# STM32WB09 register map
File version: 1.0
CPU: CM0+ r0p0, little endian, MPU, no FPU, 2 interrupt priority bits
Registers are 32-bit, read-write, reset 0x0 unless marked. A register's access mark holds for its fields unless they carry their own. Offsets are from the block's base; [hi:lo] are bit positions; {n}, {i} and the like mark numbered series.

## PWRC
Base 0x48500000
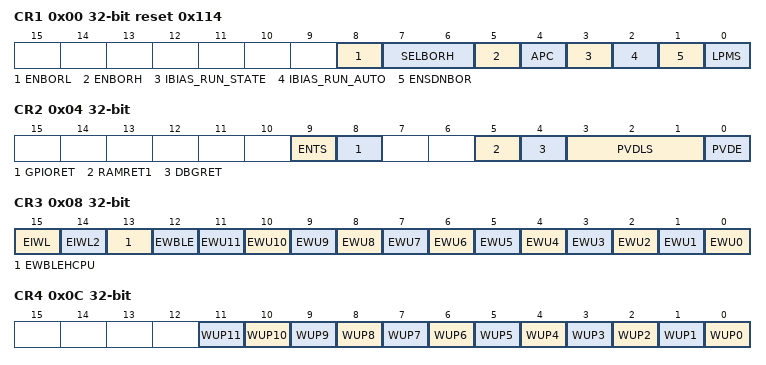
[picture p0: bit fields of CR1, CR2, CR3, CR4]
0x00 CR1 reset 0x114
  [8] ENBORL — ENBORL: Enable BORL reset supervising during RUN mode. 0: No BORL is monitored during RUN mode. 1: BORL is monitored during RUN mode (a POR reset will happen if VDDIO goes below 1.6V during RUN mode) (default). Note: Enabling this feature prevents blocking the device if VDDIO goes below supported voltages during RUN.
  [7:6] SELBORH — SELBORH[1:0]: BORH selection of Vbor threshold
  [5] ENBORH — ENBORH: enable BORH configuration
  [4] APC — APC Apply Pull-up and pull-down configuration from CPU
  [3] IBIAS_RUN_STATE — IBIAS_RUN_STATE: Enable/Disable IBIAS during RUN mode when automatic mode is disabled. 0: IBIAS control is disabled (default). 1: IBIAS control is enabled.
  [2] IBIAS_RUN_AUTO — IBIAS_RUN_AUTO: Enable automatic IBIAS control during RUN/DEEPSTOP mode. 0: IBIAS control is manual (and controlled by IBIAS_RUN_STATE register) 1: IBIAS control is automatic (default).
  [1] ENSDNBOR — ENSDNBOR: Enable BOR supply monitoring during shutdown mode.
  [0] LPMS — LPMS Low Power Mode Selection Selection of the low power mode entered when CPU enters DEEP SLEEP mode and BLE is rdy2sleep.
0x04 CR2
  [9] ENTS — ENTS: Enable Temperature Sensor
  [8] GPIORET — GPIORET: GPIO retention enable. 0: GPIO don't retain their status during DEEPSTOP and exiting from DEEPSTOP (default) 1: GPIO retain their status during DEEPSTOP and exiting from DEEPSTOP. Note: it's mandatory to ensure this bit is set before entering DEEPSTOP unless DBRG.DEEPSTOP2 bit is set.
  [5] RAMRET1 — RAMRET1: RAM1 retention during low power mode
  [4] DBGRET — DBGRET: PA2 and PA3 retention enable after DEEPSTOP 0: PA2, PA3 don't retain their status exiting from DEEPSTOP. (default) 1: PA2, PA3 retain their status exiting from DEEPSTOP.
  [3:1] PVDLS — PVDLS[2:0] Programmable Voltage Detector Level selection then PVDO=1)
  [0] PVDE — PVDE Programmable Voltage Detector Enable When this bit is set the Power Voltage Detector is enabled
0x08 CR3
  [15] EIWL — EIWL: Enable wakeup on Internal event (RTC). 0: Wakeup on internal line is disabled (default). 1: Wakeup on internal line is enabled.
  [14] EIWL2 — EIWL2: Enable wakeup on Internal event (LPUART). 0: Wakeup on internal line is disabled (default). 1: Wakeup on internal line is enabled.
  [13] EWBLEHCPU — EWBLEHCPU: Enable wakeup on BLE Host CPU event. 0: Wakeup on BLE Host CPU line is disabled (default). 1: Wakeup on BLE Host CPU line is enabled.
  [12] EWBLE — EWBLE: Enable wakeup on BLE event. 0: Wakeup on BLE line is disabled (default). 1: Wakeup on BLE line is enabled.
  [n] EWU{n} (n=8..11) — EWU{n} Enable WakeUp line {n} (PA{n}) When this bit is set the wakeup line {n} is enabled and a rising or falling edge on wakeup line {n} will trigger a CPU wakeup event depending on CR4.WP{n} bit.
  [n] EWU{n} (n=0..7) — EWU{n} Enable WakeUp line {n} (PB{n}) When this bit is set the wakeup line {n} is enabled and a rising or falling edge on wakeup line {n} will trigger a CPU wakeup event depending on CR4.WP{n} bit.
0x0C CR4
  [n] WUP{n} (n=8..11) — WUP{n} Wake-up Line Polarity {n} (PA{n}) This bit defines the polarity used for event detection on external wake-up line {n}
  [n] WUP{n} (n=0..7) — WUP{n} Wake-up Line Polarity {n} (PB{n}) This bit defines the polarity used for event detection on external wake-up line {n}
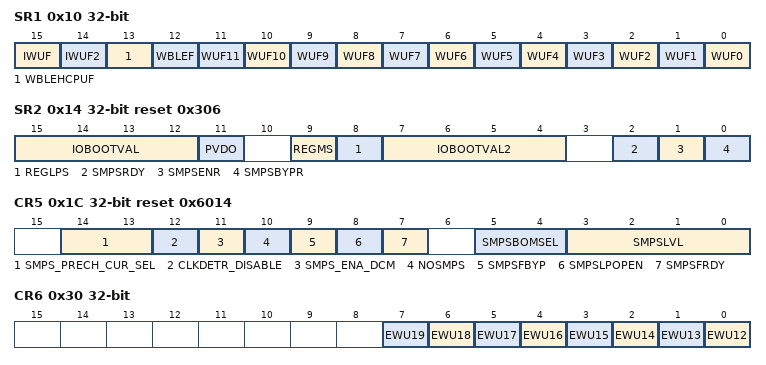
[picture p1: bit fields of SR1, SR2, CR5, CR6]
0x10 SR1
  [15] IWUF ro — IWUF: Internal wakeup flag (RTC). 0: no wakeup from RTC occurred since last clear. 1: a wakeup from RTC occurred since last clear. Note: The user must clear the RTC wakeup flag inside the RTC IP to clear this bit (mirror of the RTC wakeup line on the PWRC block).
  [14] IWUF2 ro — IWUF2: Internal wakeup 2 flag (LPUART). 0: no wakeup from LPUART occurred since last clear. 1: a wakeup from LPUART occurred since last clear. Note: The user must clear the LPUART wakeup flag inside the LPUART IP to clear this bit (mirror of the LPUART wakeup line on the PWRC block).
  [13] WBLEHCPUF — WBLEHCPUF: BLE Host CPU wakeup flag. 0: no wakeup from BLE Host CPU occurred since last clear. 1: a wakeup from BLE Host CPU occurred since last clear. Cleared by writing 1 in this bit.
  [12] WBLEF — WBLEF: BLE wakeup flag. 0: no wakeup from BLE occurred since last clear. 1: a wakeup from BLE occurred since last clear. Cleared by writing 1 in this bit.
  [n] WUF{n} (n=8..11) — WUF{n} WakeUp Flag {n} (PA{n}) This bit is set when a wakeup is detected on wakeup line {n}. It is cleared by a reset pad or by writing 1 in this bit field. writting this bit, clears the interrupt:
  [n] WUF{n} (n=0..7) — WUF{n} WakeUp Flag {n} (PB{n}) This bit is set when a wakeup is detected on wakeup line {n}. It is cleared by a reset pad or by writing 1 in this bit field. writting this bit, clears the interrupt:
0x14 SR2 ro reset 0x306
  [15:12] IOBOOTVAL — Bit3: PA11 input value on VDD33 latched at POR Bit2: PA10 input value on VDD33 latched at POR Bit1: PA9 input value on VDD33 latched at POR Bit0: PA8 input value on VDD33 latched at POR
  [11] PVDO — PVDO: Power Voltage Detector Output When the Power Voltage Detector is enabled (CR2.PVDE) this bit is set when the system supply (VDDIO) is lower than the selected PVD threshold (CR2.PVDLS)
  [9] REGMS — REGMS: Regulator Main LDO Started This bit provides the information whether main regulator is ready.
  [8] REGLPS — REGLPS: Regulator Low Power Started This bit provides the information whether low power regulator is ready.
  [7:4] IOBOOTVAL2 — Bit3: PB15 input value on VDD33 latched at POR Bit2: PB14 input value on VDD33 latched at POR Bit1: PB13 input value on VDD33 latched at POR Bit0: PB12 input value on VDD33 latched at POR
  [2] SMPSRDY — SMPSRDY: SMPS Ready Status This bit provides the information whether SMPS is ready.
  [1] SMPSENR — SMPSENR: SMPS Enable Control Replica This bit mirrors the actual ENABLE_3V3 control signal driven to the SMPS regulator, dependant on the real working state.
  [0] SMPSBYPR — SMPSBYPR: SMPS Force Bypass Control Replica This bit mirrors the actual BYPASS_3V3 control signal driven to the SMPS regulator, dependant on the real working state.
0x1C CR5 reset 0x6014
  [14:13] SMPS_PRECH_CUR_SEL — SMPS_PRECH_CUR_SEL[1:0] Selection for SMPS PRECHARGE limit current
  [12] CLKDETR_DISABLE — CLKDETR_DISABLE: disable SMPS clock detection The SMPS clock detection enables an automatic SMPS bypass switching in case of unwanted loss of SMPS clock.
  [11] SMPS_ENA_DCM — SMPS_ENA_DCM: enable discontinuous conduction mode
  [10] NOSMPS — NOSMPS: No SMPS Mode When this bit is set, the SMPS regulator will be disabled. Note that this configuration should be used only when SMPS_FB pad is directly connected to VBATT or Vext, without L/C BOM.
  [9] SMPSFBYP — SMPSFB Force SMPS Regulator in bypass mode When this bit is set, the SMPS regulator will be forced to operate in precharge mode. the actual state of SMPS can be observed thanks to the replica SR2.SMPSBYPR.
  [8] SMPSLPOPEN — SMPSLPOPEN: In Low Power mode SMPS is in OPEN mode (instead of PRECHARGE mode). When this bit is set, when the chip is in Low power mode the SMPS regulator will be disabled (HZ) Documentation needed.
  [7] SMPSFRDY — SMPSFB Force ready check When this bit is set, the SMPS FSM will consider the SMPS ready .
  [5:4] SMPSBOMSEL — SMPSBOMSEL: SMPS BOM Selection:
  [3:0] SMPSLVL — SMPSLVL[3:0] SMPS Output Level Voltage Selection Select the SMPS output voltage with a granularity of 50mV. Default = '0100' (1.4V) Vout = 1.2 + 0.05*SMPSOUT (V)
0x20 PUCRA reset 0xF07
  [15:0] PU — PU[x] : Pull Up Pull up activation on port A[i] pad when APC bit of PWRC CR3 is set
0x24 PDCRA reset 0x8
  [15:0] PD — PD[x]: Pull Down Pull Down activation on port A[i] pad when APC bit of PWRC CR3 is set
0x28 PUCRB reset 0xF0FF
  [15:0] PU — PU[x] : Pull Up Pull up activation on port B[i] pad when APC bit of PWRC CR3 is set
0x2C PDCRB
  [15:0] PD — PD[x]: Pull Down Pull Down activation on port B[i] pad when APC bit of PWRC CR3 is set
0x30 CR6
  [n-12] EWU{n} (n=16..19) — EWU{n} Enable WakeUp line {n} (PB{n-4}) When this bit is set the wakeup line {n} is enabled and a rising or falling edge on wakeup line {n-12} will trigger a CPU wakeup event depending on CR7.WP{n-12} bit.
  [n-12] EWU{n} (n=12..15) — EWU{n} Enable WakeUp line {n} (PA{n-12}) When this bit is set the wakeup line {n} is enabled and a rising or falling edge on wakeup line {n-12} will trigger a CPU wakeup event depending on CR7.WP{n-12} bit.
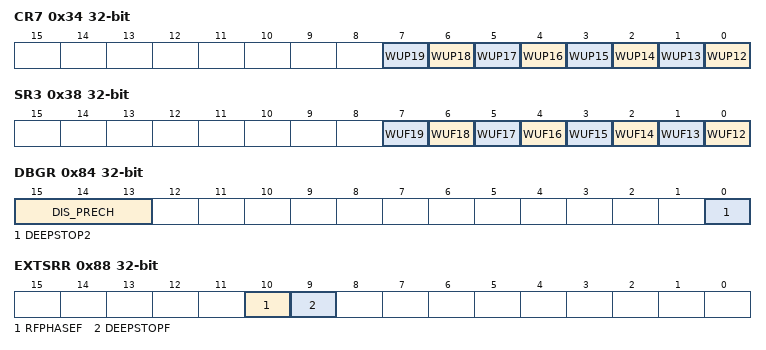
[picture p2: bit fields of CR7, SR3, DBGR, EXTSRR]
0x34 CR7
  [n-12] WUP{n} (n=16..19) — WUP{n} Wake-up Line Polarity {n} (PB{n-4}) This bit defines the polarity used for event detection on external wake-up line {n}
  [n-12] WUP{n} (n=12..15) — WUP{n} Wake-up Line Polarity {n} (PA{n-12}) This bit defines the polarity used for event detection on external wake-up line {n}
0x38 SR3
  [n-12] WUF{n} (n=16..19) — WUF{n} WakeUp Flag {n} PB{n-4} This bit is set when a wakeup is detected on wakeup line {n}. It is cleared by a reset pad or by writing 1 in this bit field. writting this bit, clears the interrupt:
  [n-12] WUF{n} (n=12..15) — WUF{n} WakeUp Flag {n} PA{n-12} This bit is set when a wakeup is detected on wakeup line {n}. It is cleared by a reset pad or by writing 1 in this bit field. writting this bit, clears the interrupt:
0x3C SDWN_WUEN — Contains Shutdown wakeup enable fields for IO.
  [0] WUEN — PB0 I/O wakeup from shutdown enable.
0x40 SDWN_WUPOL — Contains Shutdown wakeup polarity fields for IO.
  [0] WUPOL — PB0 I/O wakeup from shutdown polarity.
0x44 SDWN_WUF — Contains Shutdown wakeup flags for IO. This register is reset on PORESETn.
  [0] WUF — PB0 I/O wakeup from shutdown flag.
0x84 DBGR
  [15:13] DIS_PRECH — DIS_PRECH[2:0]: disable precharge during deepstop (debug) 111: precharge and SMPS monitoring are disabled (whatever CR5.SMPSLPOPEN) 101: precharge are activated only at deepstop exit (to be used only with CR5.SMPSLPOPEN=1) else: No effect (default 0x0)
  [0] DEEPSTOP2 — DEEPSTOP2: DEEPSTOP2 low power saving emulation enable. 0: normal DEEPSTOP will be applied 1: DEEPSTOP2 (debugger features not lost) will be applied instead of DEEPSTOP.
0x88 EXTSRR
  [10] RFPHASEF — RFPHASEF RFPHASE Flag This bit is set by hardware after a Radio wake-up event (BLE activation); it is cleared either by software, writing '1' in this bit field, or by hardware when Ready2Sleep signal is asserted by the Radio IP.
  [9] DEEPSTOPF — DEEPSTOPF System DeepStop Flag This bit is set by hardware and cleared only by a POR reset or by writing '1' in this bit field
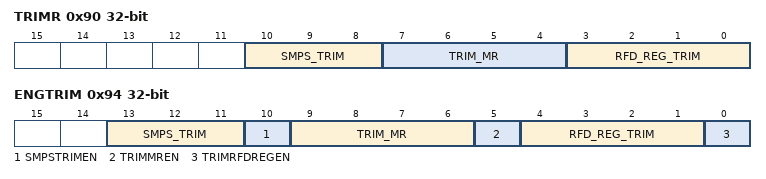
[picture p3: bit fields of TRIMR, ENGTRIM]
0x90 TRIMR access not given — This register provides the trimming values applied by hardware.
  [10:8] SMPS_TRIM — SMPS output voltage trimming.
  [7:4] TRIM_MR — Main regulator voltage trimming.
  [3:0] RFD_REG_TRIM — RF LDO trimming.
0x94 ENGTRIM — This register allows the software to overwrite the hardware trimming values.
  [13:11] SMPS_TRIM — SMPS output voltage trimming chosen by the software.
  [10] SMPSTRIMEN — SMPS_TRIM software overwrite enable.
  [9:6] TRIM_MR — Main regulator voltage trimming chosen by the software.
  [5] TRIMMREN — TRIM_MR software overwrite enable.
  [4:1] RFD_REG_TRIM — RF LDO trimming chosen by the software.
  [0] TRIMRFDREGEN — RFD_REG_TRIM software overwrite enable.
